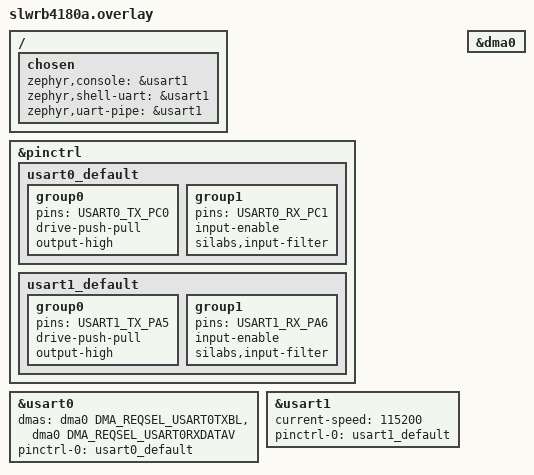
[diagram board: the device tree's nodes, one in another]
/*
 * Copyright (c) 2025, Silicon Laboratories Inc.
 *
 * SPDX-License-Identifier: Apache-2.0
 */

/*
 * Need to connect PC0 and PC1 of the Expension Pin header
 */
/ {
	chosen {
		zephyr,console = &usart1;
		zephyr,shell-uart = &usart1;
		zephyr,uart-pipe = &usart1;
	};
};

&pinctrl {
	usart0_default: usart0_default {
		group0 {
			pins = <USART0_TX_PC0>;
			drive-push-pull;
			output-high;
		};
		group1 {
			pins = <USART0_RX_PC1>;
			input-enable;
			silabs,input-filter;
		};
	};
	usart1_default: usart1_default {
		group0 {
			pins = <USART1_TX_PA5>;
			drive-push-pull;
			output-high;
		};
		group1 {
			pins = <USART1_RX_PA6>;
			input-enable;
			silabs,input-filter;
		};
	};
};

dut: &usart0 {
	dmas = <&dma0 DMA_REQSEL_USART0TXBL>,
	       <&dma0 DMA_REQSEL_USART0RXDATAV>;
	dma-names = "tx", "rx";
	pinctrl-0 = <&usart0_default>;
	pinctrl-names = "default";
};

&usart1 {
	current-speed = <115200>;
	pinctrl-0 = <&usart1_default>;
	pinctrl-names = "default";
	status = "okay";
};

&dma0 {
	status = "okay";
};
